VERSION ""

NS_ :

BS_:

BU_:

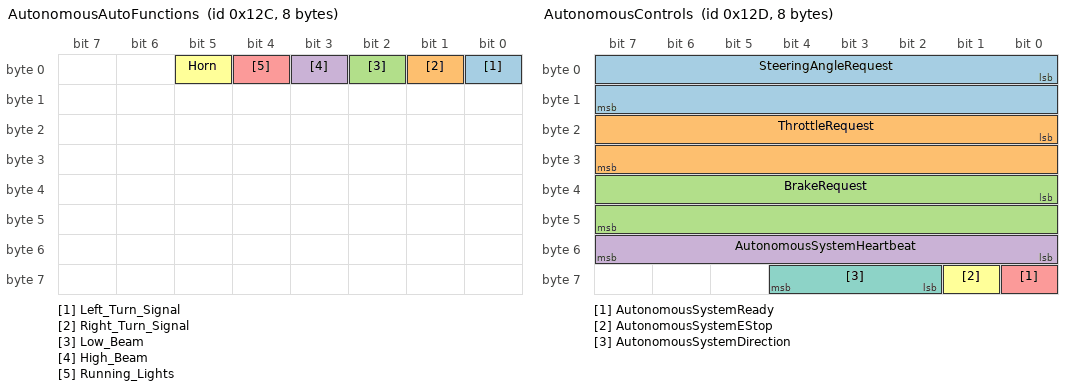
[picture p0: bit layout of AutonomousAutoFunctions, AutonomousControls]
BO_ 300 AutonomousAutoFunctions: 8 Vector__XXX
 SG_ Left_Turn_Signal : 0|1@1+ (1,0) [0|0] "" Vector__XXX
 SG_ Right_Turn_Signal : 1|1@1+ (1,0) [0|0] "" Vector__XXX
 SG_ Low_Beam : 2|1@1+ (1,0) [0|0] "" Vector__XXX
 SG_ High_Beam : 3|1@1+ (1,0) [0|0] "" Vector__XXX
 SG_ Running_Lights : 4|1@1+ (1,0) [0|0] "" Vector__XXX
 SG_ Horn : 5|1@1+ (1,0) [0|0] "" Vector__XXX

BO_ 301 AutonomousControls: 8 Vector__XXX
 SG_ SteeringAngleRequest : 0|16@1- (0.1,0) [-23|23] "deg" Vector__XXX
 SG_ ThrottleRequest : 16|16@1+ (0.1,0) [0|100] "percent" Vector__XXX
 SG_ BrakeRequest : 32|16@1+ (1,0) [0|600] "PSI" Vector__XXX
 SG_ AutonomousSystemHeartbeat : 48|8@1+ (1,0) [0|255] "" Vector__XXX
 SG_ AutonomousSystemReady : 56|1@1+ (1,0) [0|1] "" Vector__XXX
 SG_ AutonomousSystemEStop : 57|1@1+ (1,0) [0|1] "" Vector__XXX
 SG_ AutonomousSystemDirection : 58|3@1+ (1,0) [1|4] "" Vector__XXX

BO_ 400 AutonomousFeedbackDynamics: 8 Vector__XXX
 SG_ WheelSpeed : 0|10@1+ (0.0625,0) [0|0] "MPH" Vector__XXX

BO_ 401 AutonomousFeedbackControls: 8 Vector__XXX
 SG_ DriversBrakePedalPressure : 16|16@1+ (1,0) [0|0] "mv" Vector__XXX
 SG_ SteeringAngleDeg : 32|16@1- (0.01,0) [0|0] "Deg" Vector__XXX

BO_ 402 AutonomousFeedbackStates: 8 Vector__XXX
 SG_ CruiseState : 0|8@1+ (1,0) [0|0] "" Vector__XXX
 SG_ DirectionState : 8|2@1+ (1,0) [0|0] "" Vector__XXX
 SG_ LeftBlindSpot : 16|1@1+ (1,0) [0|0] "" Vector__XXX
 SG_ RightBlindSpot : 24|1@1+ (1,0) [0|0] "" Vector__XXX
 SG_ ButtonEvent : 32|8@1+ (1,0) [0|0] "" Vector__XXX
 SG_ GasPressed : 40|1@1+ (1,0) [0|0] "" Vector__XXX
 SG_ BrakePressed : 41|1@1+ (1,0) [0|0] "" Vector__XXX
 SG_ ParkingBrakeSet : 42|1@1+ (1,0) [0|0] "" Vector__XXX
 SG_ SteerFaultTemporary : 43|1@1+ (1,0) [0|0] "" Vector__XXX
 SG_ SteerFaultPermanent : 44|1@1+ (1,0) [0|0] "" Vector__XXX
 SG_ SteeringPressed : 45|1@1+ (1,0) [0|0] "" Vector__XXX
 SG_ epsDisabled : 46|1@1+ (1,0) [0|0] "" Vector__XXX
 SG_ LeftBlinker : 48|1@1+ (1,0) [0|0] "" Vector__XXX
 SG_ RightBlinker : 49|1@1+ (1,0) [0|0] "" Vector__XXX
 SG_ DoorOpen : 50|1@1+ (1,0) [0|0] "" Vector__XXX
 SG_ SeatBeltUnlatched : 51|1@1+ (1,0) [0|0] "" Vector__XXX
 SG_ accFaulted : 52|1@1+ (1,0) [0|0] "" Vector__XXX

CM_ SG_ 301 SteeringAngleRequest "Angle Request in tenth of Deg (0-23)";
CM_ SG_ 301 ThrottleRequest "Percent Throttle in tenths 0-100%";
CM_ SG_ 301 BrakeRequest "BrakeDeceleration in hundreths m/s2";
CM_ SG_ 301 AutonomousSystemHeartbeat "Counter to 255";
CM_ SG_ 301 AutonomousSystemReady "True when Autonomous system is ready";
CM_ SG_ 301 AutonomousSystemEStop "True When E_Stop is Requested";
CM_ SG_ 301 AutonomousSystemDirection "Direction State: 1=Forward, 2=Reverse, 3=Park, 4=Nutral";
CM_ SG_ 401 DriversBrakePedalPressure "Will convert to PSI later";
